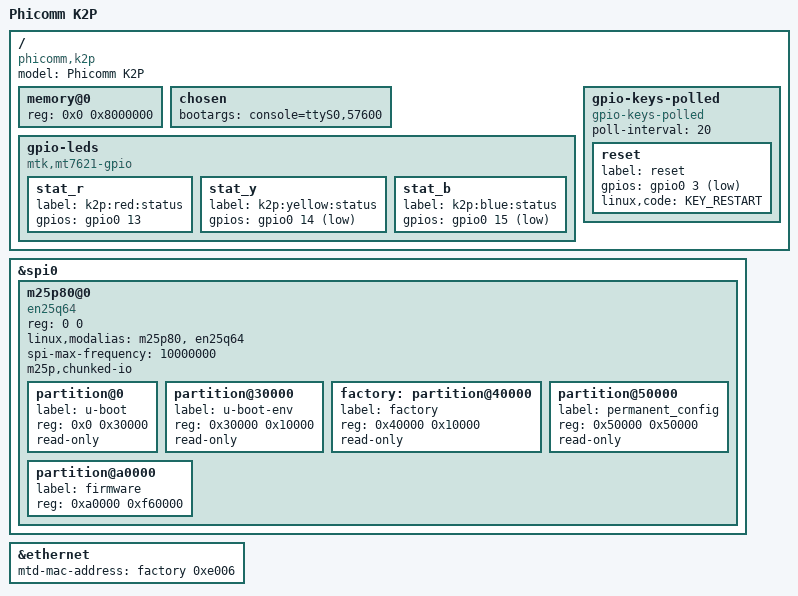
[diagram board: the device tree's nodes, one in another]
/dts-v1/;

/include/ "mt7621.dtsi"

/ {
	compatible = "phicomm,k2p", "ralink,mt7621-soc";
	model = "Phicomm K2P";

	memory@0 {
		reg = <0x0 0x8000000>;
	};

	chosen {
		bootargs = "console=ttyS0,57600";
	};

	gpio-leds {
		compatible = "mtk,mt7621-gpio";

		stat_r {
			label = "k2p:red:status";
			gpios = <&gpio0 13 GPIO_ACTIVE_HIGH>;
		};

		stat_y {
			label = "k2p:yellow:status";
			gpios = <&gpio0 14 GPIO_ACTIVE_LOW>;
		};

		stat_b {
			label = "k2p:blue:status";
			gpios = <&gpio0 15 GPIO_ACTIVE_LOW>;
		};
	};

	gpio-keys-polled {
		compatible = "gpio-keys-polled";
		#address-cells = <1>;
		#size-cells = <0>;
		poll-interval = <20>;

		reset {
			label = "reset";
			gpios = <&gpio0 3 GPIO_ACTIVE_LOW>;
			linux,code = <KEY_RESTART>;
		};
	};
};

&spi0 {
	status = "okay";

	m25p80@0 {
		#address-cells = <1>;
		#size-cells = <1>;
		compatible = "en25q64";
		reg = <0 0>;
		linux,modalias = "m25p80", "en25q64";
		spi-max-frequency = <10000000>;

		m25p,chunked-io;

		partition@0 {
			label = "u-boot";
			reg = <0x0 0x30000>;
			read-only;
		};

		partition@30000 {
			label = "u-boot-env";
			reg = <0x30000 0x10000>;
			read-only;
		};

		factory: partition@40000 {
			label = "factory";
			reg = <0x40000 0x10000>;
			read-only;
		};

		partition@50000 {
			label = "permanent_config";
			reg = <0x50000 0x50000>;
			read-only;
		};

		partition@a0000 {
			label = "firmware";
			reg = <0xa0000 0xf60000>;
		};
	};
};

&ethernet {
	mtd-mac-address = <&factory 0xe006>;
};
